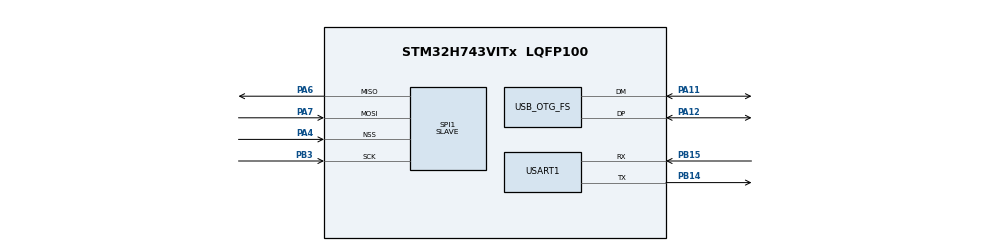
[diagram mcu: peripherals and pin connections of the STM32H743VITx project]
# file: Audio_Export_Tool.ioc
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CORTEX_M7.AccessPermission-Cortex_Memory_Protection_Unit_Region0_Settings=MPU_REGION_FULL_ACCESS
CORTEX_M7.AccessPermission-Cortex_Memory_Protection_Unit_Region1_Settings=MPU_REGION_FULL_ACCESS
CORTEX_M7.BaseAddress-Cortex_Memory_Protection_Unit_Region0_Settings=0x24000000
CORTEX_M7.BaseAddress-Cortex_Memory_Protection_Unit_Region1_Settings=0x38000000
CORTEX_M7.CPU_DCache=Disabled
CORTEX_M7.CPU_ICache=Enabled
CORTEX_M7.Enable-Cortex_Memory_Protection_Unit_Region0_Settings=MPU_REGION_ENABLE
CORTEX_M7.Enable-Cortex_Memory_Protection_Unit_Region1_Settings=MPU_REGION_ENABLE
CORTEX_M7.IsBufferable-Cortex_Memory_Protection_Unit_Region0_Settings=MPU_ACCESS_BUFFERABLE
CORTEX_M7.IsCacheable-Cortex_Memory_Protection_Unit_Region0_Settings=MPU_ACCESS_CACHEABLE
CORTEX_M7.IsCacheable-Cortex_Memory_Protection_Unit_Region1_Settings=MPU_ACCESS_CACHEABLE
CORTEX_M7.IsShareable-Cortex_Memory_Protection_Unit_Region1_Settings=MPU_ACCESS_SHAREABLE
CORTEX_M7.MPU_Control=__NULL
CORTEX_M7.Size-Cortex_Memory_Protection_Unit_Region0_Settings=MPU_REGION_SIZE_512KB
CORTEX_M7.Size-Cortex_Memory_Protection_Unit_Region1_Settings=MPU_REGION_SIZE_64KB
CORTEX_M7.TypeExtField-Cortex_Memory_Protection_Unit_Region0_Settings=MPU_TEX_LEVEL1
CORTEX_M7.TypeExtField-Cortex_Memory_Protection_Unit_Region1_Settings=MPU_TEX_LEVEL1
Dma.Request0=SPI1_RX
Dma.Request1=SPI1_TX
Dma.Request2=USART1_RX
Dma.Request3=USART1_TX
Dma.SPI1_RX.0.Direction=DMA_PERIPH_TO_MEMORY
Dma.SPI1_RX.0.EventEnable=DISABLE
Dma.SPI1_RX.0.FIFOMode=DMA_FIFOMODE_DISABLE
Dma.SPI1_RX.0.Instance=DMA1_Stream0
Dma.SPI1_RX.0.MemDataAlignment=DMA_MDATAALIGN_BYTE
Dma.SPI1_RX.0.MemInc=DMA_MINC_ENABLE
Dma.SPI1_RX.0.Mode=DMA_CIRCULAR
Dma.SPI1_RX.0.PeriphDataAlignment=DMA_PDATAALIGN_BYTE
Dma.SPI1_RX.0.PeriphInc=DMA_PINC_DISABLE
Dma.SPI1_RX.0.Polarity=HAL_DMAMUX_REQ_GEN_RISING
Dma.SPI1_RX.0.Priority=DMA_PRIORITY_LOW
Dma.SPI1_RX.0.RequestNumber=1
Dma.SPI1_RX.0.SignalID=NONE
Dma.SPI1_RX.0.SyncEnable=DISABLE
Dma.SPI1_RX.0.SyncPolarity=HAL_DMAMUX_SYNC_NO_EVENT
Dma.SPI1_RX.0.SyncRequestNumber=1
Dma.SPI1_RX.0.SyncSignalID=NONE
Dma.SPI1_TX.1.Direction=DMA_MEMORY_TO_PERIPH
Dma.SPI1_TX.1.EventEnable=DISABLE
Dma.SPI1_TX.1.FIFOMode=DMA_FIFOMODE_DISABLE
Dma.SPI1_TX.1.Instance=DMA1_Stream1
Dma.SPI1_TX.1.MemDataAlignment=DMA_MDATAALIGN_BYTE
Dma.SPI1_TX.1.MemInc=DMA_MINC_ENABLE
Dma.SPI1_TX.1.Mode=DMA_CIRCULAR
Dma.SPI1_TX.1.PeriphDataAlignment=DMA_PDATAALIGN_BYTE
Dma.SPI1_TX.1.PeriphInc=DMA_PINC_DISABLE
Dma.SPI1_TX.1.Polarity=HAL_DMAMUX_REQ_GEN_RISING
Dma.SPI1_TX.1.Priority=DMA_PRIORITY_LOW
Dma.SPI1_TX.1.RequestNumber=1
Dma.SPI1_TX.1.SignalID=NONE
Dma.SPI1_TX.1.SyncEnable=DISABLE
Dma.SPI1_TX.1.SyncPolarity=HAL_DMAMUX_SYNC_NO_EVENT
Dma.SPI1_TX.1.SyncRequestNumber=1
Dma.SPI1_TX.1.SyncSignalID=NONE
Dma.USART1_RX.2.Direction=DMA_PERIPH_TO_MEMORY
Dma.USART1_RX.2.EventEnable=DISABLE
Dma.USART1_RX.2.FIFOMode=DMA_FIFOMODE_DISABLE
Dma.USART1_RX.2.Instance=DMA1_Stream2
Dma.USART1_RX.2.MemDataAlignment=DMA_MDATAALIGN_BYTE
Dma.USART1_RX.2.MemInc=DMA_MINC_ENABLE
Dma.USART1_RX.2.Mode=DMA_NORMAL
Dma.USART1_RX.2.PeriphDataAlignment=DMA_PDATAALIGN_BYTE
Dma.USART1_RX.2.PeriphInc=DMA_PINC_DISABLE
Dma.USART1_RX.2.Polarity=HAL_DMAMUX_REQ_GEN_RISING
Dma.USART1_RX.2.Priority=DMA_PRIORITY_LOW
Dma.USART1_RX.2.RequestNumber=1
Dma.USART1_RX.2.SignalID=NONE
Dma.USART1_RX.2.SyncEnable=DISABLE
Dma.USART1_RX.2.SyncPolarity=HAL_DMAMUX_SYNC_NO_EVENT
Dma.USART1_RX.2.SyncRequestNumber=1
Dma.USART1_RX.2.SyncSignalID=NONE
Dma.USART1_TX.3.Direction=DMA_MEMORY_TO_PERIPH
Dma.USART1_TX.3.EventEnable=DISABLE
Dma.USART1_TX.3.FIFOMode=DMA_FIFOMODE_DISABLE
Dma.USART1_TX.3.Instance=DMA1_Stream3
Dma.USART1_TX.3.MemDataAlignment=DMA_MDATAALIGN_BYTE
Dma.USART1_TX.3.MemInc=DMA_MINC_ENABLE
Dma.USART1_TX.3.Mode=DMA_NORMAL
Dma.USART1_TX.3.PeriphDataAlignment=DMA_PDATAALIGN_BYTE
Dma.USART1_TX.3.PeriphInc=DMA_PINC_DISABLE
Dma.USART1_TX.3.Polarity=HAL_DMAMUX_REQ_GEN_RISING
Dma.USART1_TX.3.Priority=DMA_PRIORITY_LOW
Dma.USART1_TX.3.RequestNumber=1
Dma.USART1_TX.3.SignalID=NONE
Dma.USART1_TX.3.SyncEnable=DISABLE
Dma.USART1_TX.3.SyncPolarity=HAL_DMAMUX_SYNC_NO_EVENT
Dma.USART1_TX.3.SyncRequestNumber=1
Dma.USART1_TX.3.SyncSignalID=NONE
FREERTOS.Events01=Audio_Rec_Event,Static,Audio_Rec_EventControlBlock
FREERTOS.Tasks01=defaultTask,24,4096,StartDefaultTask,Default,NULL,Static,defaultTaskBuffer,defaultTaskControlBlock;Audio_Task,24,4096,StartAudio_Task,Default,NULL,Static,Audio_TaskBuffer,Audio_TaskControlBlock
FREERTOS.configENABLE_FPU=1
FREERTOS.configTOTAL_HEAP_SIZE=2048
Mcu.Family=STM32H7
Mcu.Name=STM32H743VITx
Mcu.Package=LQFP100
NVIC.DMA1_Stream0_IRQn=true\:5\:0\:false\:false\:true\:true\:false\:true
NVIC.DMA1_Stream1_IRQn=true\:5\:0\:false\:false\:true\:true\:false\:true
NVIC.DMA1_Stream2_IRQn=true\:5\:0\:false\:false\:true\:true\:false\:true
NVIC.DMA1_Stream3_IRQn=true\:5\:0\:false\:false\:true\:true\:false\:true
NVIC.OTG_FS_IRQn=true\:5\:0\:false\:false\:true\:true\:false\:true
NVIC.PriorityGroup=NVIC_PRIORITYGROUP_4
NVIC.SPI1_IRQn=true\:5\:0\:false\:false\:true\:true\:false\:true
NVIC.TIM1_UP_IRQn=true\:15\:0\:false\:false\:true\:false\:false\:true
NVIC.TIM2_IRQn=true\:5\:0\:false\:false\:true\:true\:true\:true
NVIC.TimeBase=TIM1_UP_IRQn
NVIC.TimeBaseIP=TIM1
NVIC.USART1_IRQn=true\:5\:0\:false\:false\:true\:true\:true\:true
PA11.Mode=Device_Only
PA11.Signal=USB_OTG_FS_DM
PA12.Mode=Device_Only
PA12.Signal=USB_OTG_FS_DP
PA13\ (JTMS/SWDIO).Mode=Serial_Wire
PA13\ (JTMS/SWDIO).Signal=DEBUG_JTMS-SWDIO
PA14\ (JTCK/SWCLK).Mode=Serial_Wire
PA14\ (JTCK/SWCLK).Signal=DEBUG_JTCK-SWCLK
PA4.GPIO_PuPd=GPIO_NOPULL
PA4.Mode=NSS_Signal_Hard_Input
PA4.Signal=SPI1_NSS
PA6.Mode=Full_Duplex_Slave
PA6.Signal=SPI1_MISO
PA7.Mode=Full_Duplex_Slave
PA7.Signal=SPI1_MOSI
PB14.Mode=Asynchronous
PB14.Signal=USART1_TX
PB15.Mode=Asynchronous
PB15.Signal=USART1_RX
PB3\ (JTDO/TRACESWO).Mode=Full_Duplex_Slave
PB3\ (JTDO/TRACESWO).Signal=SPI1_SCK
PH0-OSC_IN\ (PH0).Mode=HSE-External-Oscillator
PH0-OSC_IN\ (PH0).Signal=RCC_OSC_IN
PH1-OSC_OUT\ (PH1).Mode=HSE-External-Oscillator
PH1-OSC_OUT\ (PH1).Signal=RCC_OSC_OUT
ProjectManager.HeapSize=0x1000
ProjectManager.StackSize=0xA000
ProjectManager.TargetToolchain=EWARM V8.32
RCC.ADCFreq_Value=96000000
RCC.APB1Freq_Value=120000000
RCC.APB2Freq_Value=120000000
RCC.APB3Freq_Value=120000000
RCC.APB4Freq_Value=120000000
RCC.CKPERSourceSelection=RCC_CLKPSOURCE_HSE
RCC.CortexFreq_Value=480000000
RCC.D1PPRE=RCC_APB3_DIV2
RCC.D2PPRE1=RCC_APB1_DIV2
RCC.D2PPRE2=RCC_APB2_DIV2
RCC.D3PPRE=RCC_APB4_DIV2
RCC.DIVM1=5
RCC.DIVM2=25
RCC.DIVM3=25
RCC.DIVN1=192
RCC.DIVN2=192
RCC.DIVN3=192
RCC.DIVP3=4
RCC.DIVQ3=4
RCC.HCLKFreq_Value=240000000
RCC.HPRE=RCC_HCLK_DIV2
RCC.PLLSourceVirtual=RCC_PLLSOURCE_HSE
RCC.SPI123CLockSelection=RCC_SPI123CLKSOURCE_PLL3
RCC.SYSCLKFreq_VALUE=480000000
RCC.SYSCLKSource=RCC_SYSCLKSOURCE_PLLCLK
RCC.USBCLockSelection=RCC_USBCLKSOURCE_PLL3
RCC.USBFreq_Value=48000000
SPI1.DataSize=SPI_DATASIZE_8BIT
SPI1.Direction=SPI_DIRECTION_2LINES
SPI1.Mode=SPI_MODE_SLAVE
SPI1.VirtualNSS=VM_NSSHARD
SPI1.VirtualType=VM_SLAVE
TIM2.AutoReloadPreload=TIM_AUTORELOAD_PRELOAD_ENABLE
TIM2.Period=1000-1
TIM2.Prescaler=240-1
USART1.VirtualMode-Asynchronous=VM_ASYNC
USB_DEVICE.CLASS_NAME_FS=AUDIO
USB_DEVICE.PID_AUDIO_FS=0x5730
USB_DEVICE.USBD_AUDIO_FREQ-AUDIO_FS=16000
USB_DEVICE.VirtualMode-AUDIO_FS=Audio
USB_DEVICE.VirtualModeFS=Audio_FS
USB_OTG_FS.VirtualMode=Device_Only
VP_FREERTOS_VS_CMSIS_V2.Mode=CMSIS_V2
VP_SYS_VS_tim1.Mode=TIM1
VP_TIM2_VS_ClockSourceINT.Mode=Internal
VP_USB_DEVICE_VS_USB_DEVICE_AUDIO_FS.Mode=AUDIO_FS
board=custom

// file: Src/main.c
/* USER CODE BEGIN Header */
/**
  ******************************************************************************
  * @file           : main.c
  * @brief          : Main program body
  ******************************************************************************
  * @attention
  *
  * <h2><center>&copy; Copyright (c) 2021 STMicroelectronics.
  * All rights reserved.</center></h2>
  *
  * This software component is licensed by ST under Ultimate Liberty license
  * SLA0044, the "License"; You may not use this file except in compliance with
  * the License. You may obtain a copy of the License at:
  *                             www.st.com/SLA0044
  *
  ******************************************************************************
  */
/* USER CODE END Header */
#include "main.h"
#include "cmsis_os.h"
#include "dma.h"
#include "spi.h"
#include "tim.h"
#include "usart.h"
#include "usb_device.h"
#include "gpio.h"

void SystemClock_Config(void);
void PeriphCommonClock_Config(void);
static void MPU_Config(void);
void MX_FREERTOS_Init(void);

int main(void)
{

  /* MPU Configuration--------------------------------------------------------*/
  //MPU_Config();

  /* Enable I-Cache---------------------------------------------------------*/
  SCB_EnableICache();

  /* Enable D-Cache---------------------------------------------------------*/
  //SCB_EnableDCache();

  /* MCU Configuration--------------------------------------------------------*/

  /* Reset of all peripherals, Initializes the Flash interface and the Systick. */
  HAL_Init();

  /* Configure the system clock */
  SystemClock_Config();

/* Configure the peripherals common clocks */
  PeriphCommonClock_Config();

  /* Initialize all configured peripherals */
  MX_GPIO_Init();
  MX_DMA_Init();
  MX_SPI1_Init();
  MX_TIM2_Init();
  MX_USART1_UART_Init();

  /* Init scheduler */
  osKernelInitialize();  /* Call init function for freertos objects (in freertos.c) */
  MX_FREERTOS_Init();
  /* Start scheduler */
  osKernelStart();

  /* We should never get here as control is now taken by the scheduler */
  /* Infinite loop */
  while (1)
  {

  }
}

void SystemClock_Config(void)
{
  RCC_OscInitTypeDef RCC_OscInitStruct = {0};
  RCC_ClkInitTypeDef RCC_ClkInitStruct = {0};

  /** Supply configuration update enable
  */
  HAL_PWREx_ConfigSupply(PWR_LDO_SUPPLY);
  /** Configure the main internal regulator output voltage
  */
  __HAL_PWR_VOLTAGESCALING_CONFIG(PWR_REGULATOR_VOLTAGE_SCALE0);

  while(!__HAL_PWR_GET_FLAG(PWR_FLAG_VOSRDY)) {}
  /** Macro to configure the PLL clock source
  */
  __HAL_RCC_PLL_PLLSOURCE_CONFIG(RCC_PLLSOURCE_HSE);
  /** Initializes the RCC Oscillators according to the specified parameters
  * in the RCC_OscInitTypeDef structure.
  */
  RCC_OscInitStruct.OscillatorType = RCC_OSCILLATORTYPE_HSE;
  RCC_OscInitStruct.HSEState = RCC_HSE_ON;
  RCC_OscInitStruct.PLL.PLLState = RCC_PLL_ON;
  RCC_OscInitStruct.PLL.PLLSource = RCC_PLLSOURCE_HSE;
  RCC_OscInitStruct.PLL.PLLM = 5;
  RCC_OscInitStruct.PLL.PLLN = 192;
  RCC_OscInitStruct.PLL.PLLP = 2;
  RCC_OscInitStruct.PLL.PLLQ = 2;
  RCC_OscInitStruct.PLL.PLLR = 2;
  RCC_OscInitStruct.PLL.PLLRGE = RCC_PLL1VCIRANGE_2;
  RCC_OscInitStruct.PLL.PLLVCOSEL = RCC_PLL1VCOWIDE;
  RCC_OscInitStruct.PLL.PLLFRACN = 0;
  if (HAL_RCC_OscConfig(&RCC_OscInitStruct) != HAL_OK)
  {
    Error_Handler();
  }
  /** Initializes the CPU, AHB and APB buses clocks
  */
  RCC_ClkInitStruct.ClockType = RCC_CLOCKTYPE_HCLK|RCC_CLOCKTYPE_SYSCLK
                              |RCC_CLOCKTYPE_PCLK1|RCC_CLOCKTYPE_PCLK2
                              |RCC_CLOCKTYPE_D3PCLK1|RCC_CLOCKTYPE_D1PCLK1;
  RCC_ClkInitStruct.SYSCLKSource = RCC_SYSCLKSOURCE_PLLCLK;
  RCC_ClkInitStruct.SYSCLKDivider = RCC_SYSCLK_DIV1;
  RCC_ClkInitStruct.AHBCLKDivider = RCC_HCLK_DIV2;
  RCC_ClkInitStruct.APB3CLKDivider = RCC_APB3_DIV2;
  RCC_ClkInitStruct.APB1CLKDivider = RCC_APB1_DIV2;
  RCC_ClkInitStruct.APB2CLKDivider = RCC_APB2_DIV2;
  RCC_ClkInitStruct.APB4CLKDivider = RCC_APB4_DIV2;

  if (HAL_RCC_ClockConfig(&RCC_ClkInitStruct, FLASH_LATENCY_4) != HAL_OK)
  {
    Error_Handler();
  }
}

void PeriphCommonClock_Config(void)
{
  RCC_PeriphCLKInitTypeDef PeriphClkInitStruct = {0};

  /** Initializes the peripherals clock
  */
  PeriphClkInitStruct.PeriphClockSelection = RCC_PERIPHCLK_USB|RCC_PERIPHCLK_SPI1;
  PeriphClkInitStruct.PLL3.PLL3M = 25;
  PeriphClkInitStruct.PLL3.PLL3N = 192;
  PeriphClkInitStruct.PLL3.PLL3P = 4;
  PeriphClkInitStruct.PLL3.PLL3Q = 4;
  PeriphClkInitStruct.PLL3.PLL3R = 2;
  PeriphClkInitStruct.PLL3.PLL3RGE = RCC_PLL3VCIRANGE_0;
  PeriphClkInitStruct.PLL3.PLL3VCOSEL = RCC_PLL3VCOWIDE;
  PeriphClkInitStruct.PLL3.PLL3FRACN = 0;
  PeriphClkInitStruct.Spi123ClockSelection = RCC_SPI123CLKSOURCE_PLL3;
  PeriphClkInitStruct.UsbClockSelection = RCC_USBCLKSOURCE_PLL3;
  if (HAL_RCCEx_PeriphCLKConfig(&PeriphClkInitStruct) != HAL_OK)
  {
    Error_Handler();
  }
}

/* MPU Configuration */

void MPU_Config(void)
{
  MPU_Region_InitTypeDef MPU_InitStruct = {0};

  /* Disables the MPU */
  HAL_MPU_Disable();
  /** Initializes and configures the Region and the memory to be protected
  */
  MPU_InitStruct.Enable = MPU_REGION_ENABLE;
  MPU_InitStruct.Number = MPU_REGION_NUMBER0;
  MPU_InitStruct.BaseAddress = 0x24000000;
  MPU_InitStruct.Size = MPU_REGION_SIZE_512KB;
  MPU_InitStruct.SubRegionDisable = 0x0;
  MPU_InitStruct.TypeExtField = MPU_TEX_LEVEL1;
  MPU_InitStruct.AccessPermission = MPU_REGION_FULL_ACCESS;
  MPU_InitStruct.DisableExec = MPU_INSTRUCTION_ACCESS_ENABLE;
  MPU_InitStruct.IsShareable = MPU_ACCESS_NOT_SHAREABLE;
  MPU_InitStruct.IsCacheable = MPU_ACCESS_CACHEABLE;
  MPU_InitStruct.IsBufferable = MPU_ACCESS_BUFFERABLE;

  HAL_MPU_ConfigRegion(&MPU_InitStruct);
  /** Initializes and configures the Region and the memory to be protected
  */
  MPU_InitStruct.Number = MPU_REGION_NUMBER1;
  MPU_InitStruct.BaseAddress = 0x38000000;
  MPU_InitStruct.Size = MPU_REGION_SIZE_64KB;
  MPU_InitStruct.IsShareable = MPU_ACCESS_SHAREABLE;
  MPU_InitStruct.IsBufferable = MPU_ACCESS_NOT_BUFFERABLE;

  HAL_MPU_ConfigRegion(&MPU_InitStruct);
  /* Enables the MPU */
  HAL_MPU_Enable(MPU_HFNMI_PRIVDEF);

}

void HAL_TIM_PeriodElapsedCallback(TIM_HandleTypeDef *htim)
{
  if (htim->Instance == TIM1) {
    HAL_IncTick();
  }
  /* USER CODE BEGIN Callback 1 */
  if(htim->Instance == TIM2)
  {
    Timer_Port_IRQHandler();
  }
  /* USER CODE END Callback 1 */
}

void Error_Handler(void)
{
  __disable_irq();
  while (1)
  {
  }
}

/************************ (C) COPYRIGHT STMicroelectronics *****END OF FILE****/

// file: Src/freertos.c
/* USER CODE BEGIN Header */
/**
  ******************************************************************************
  * File Name          : freertos.c
  * Description        : Code for freertos applications
  ******************************************************************************
  * @attention
  *
  * <h2><center>&copy; Copyright (c) 2021 STMicroelectronics.
  * All rights reserved.</center></h2>
  *
  * This software component is licensed by ST under Ultimate Liberty license
  * SLA0044, the "License"; You may not use this file except in compliance with
  * the License. You may obtain a copy of the License at:
  *                             www.st.com/SLA0044
  *
  ******************************************************************************
  */
/* USER CODE END Header */

#include "FreeRTOS.h"
#include "task.h"
#include "main.h"
#include "cmsis_os.h"

typedef StaticTask_t osStaticThreadDef_t;
typedef StaticEventGroup_t osStaticEventGroupDef_t;

/* Definitions for defaultTask */
osThreadId_t defaultTaskHandle;
uint32_t defaultTaskBuffer[ 4096 ];
osStaticThreadDef_t defaultTaskControlBlock;
const osThreadAttr_t defaultTask_attributes = {
  .name = "defaultTask",
  .cb_mem = &defaultTaskControlBlock,
  .cb_size = sizeof(defaultTaskControlBlock),
  .stack_mem = &defaultTaskBuffer[0],
  .stack_size = sizeof(defaultTaskBuffer),
  .priority = (osPriority_t) osPriorityNormal,
};
/* Definitions for Audio_Task */
osThreadId_t Audio_TaskHandle;
uint32_t Audio_TaskBuffer[ 4096 ];
osStaticThreadDef_t Audio_TaskControlBlock;
const osThreadAttr_t Audio_Task_attributes = {
  .name = "Audio_Task",
  .cb_mem = &Audio_TaskControlBlock,
  .cb_size = sizeof(Audio_TaskControlBlock),
  .stack_mem = &Audio_TaskBuffer[0],
  .stack_size = sizeof(Audio_TaskBuffer),
  .priority = (osPriority_t) osPriorityNormal,
};
/* Definitions for Audio_Rec_Event */
osEventFlagsId_t Audio_Rec_EventHandle;
osStaticEventGroupDef_t Audio_Rec_EventControlBlock;
const osEventFlagsAttr_t Audio_Rec_Event_attributes = {
  .name = "Audio_Rec_Event",
  .cb_mem = &Audio_Rec_EventControlBlock,
  .cb_size = sizeof(Audio_Rec_EventControlBlock),
};

void StartDefaultTask(void *argument);
void StartAudio_Task(void *argument);

extern void MX_USB_DEVICE_Init(void);
void MX_FREERTOS_Init(void); /* (MISRA C 2004 rule 8.1) */

void MX_FREERTOS_Init(void) {

  /* Create the thread(s) */
  /* creation of defaultTask */
  defaultTaskHandle = osThreadNew(StartDefaultTask, NULL, &defaultTask_attributes);

  /* creation of Audio_Task */
  Audio_TaskHandle = osThreadNew(StartAudio_Task, NULL, &Audio_Task_attributes);

  /* Create the event(s) */
  /* creation of Audio_Rec_Event */
  Audio_Rec_EventHandle = osEventFlagsNew(&Audio_Rec_Event_attributes);

}

void StartDefaultTask(void *argument)
{
  /* init code for USB_DEVICE */
  MX_USB_DEVICE_Init();
  /* USER CODE BEGIN StartDefaultTask */
  User_Main_Init();
  /* Infinite loop */
  for(;;)
  {
    User_Main_Loop();

    osDelay(1);
  }
  /* USER CODE END StartDefaultTask */
}

void StartAudio_Task(void *argument)
{
  /* USER CODE BEGIN StartAudio_Task */
  /*定时自动时序条件*/
//  static uint32_t Time_ms = 0;
  /* Infinite loop */
  for(;;)
  {
//    uint32_t Current_Time_ms = Timer_Port_Get_Current_Time(TIMER_MS);
//    if((Current_Time_ms - Time_ms) >= (uint32_t)ONE_FRAME_TIME_MS)
//    {
//      osEventFlagsSet(Audio_Rec_EventHandle, 1);
//      Time_ms = Current_Time_ms;
//    }
    Audio_Debug_Start();
    osDelay(1);
  }
  /* USER CODE END StartAudio_Task */
}

/************************ (C) COPYRIGHT STMicroelectronics *****END OF FILE****/
